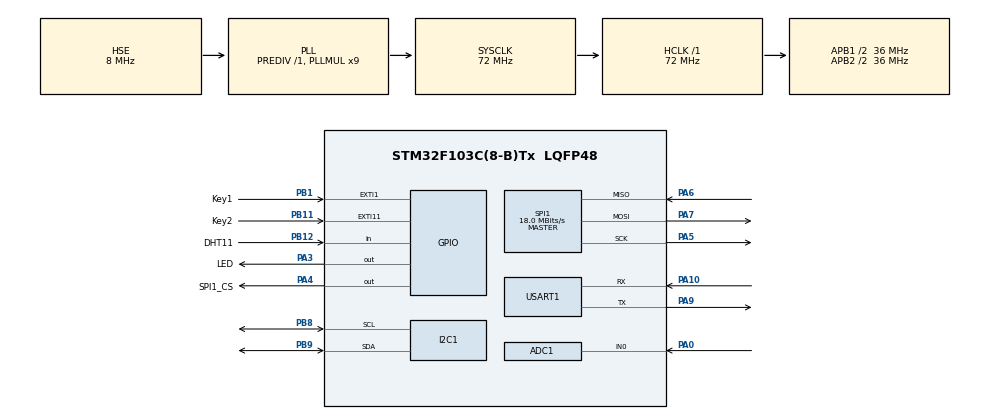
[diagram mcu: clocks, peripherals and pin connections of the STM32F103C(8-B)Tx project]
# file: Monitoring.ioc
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ADC1.Channel-0\#ChannelRegularConversion=ADC_CHANNEL_0
ADC1.ContinuousConvMode=DISABLE
ADC1.NbrOfConversionFlag=1
ADC1.Rank-0\#ChannelRegularConversion=1
ADC1.SamplingTime-0\#ChannelRegularConversion=ADC_SAMPLETIME_1CYCLE_5
ADC1.master=1
Dma.ADC1.2.Direction=DMA_PERIPH_TO_MEMORY
Dma.ADC1.2.Instance=DMA1_Channel1
Dma.ADC1.2.MemDataAlignment=DMA_MDATAALIGN_HALFWORD
Dma.ADC1.2.MemInc=DMA_MINC_ENABLE
Dma.ADC1.2.Mode=DMA_NORMAL
Dma.ADC1.2.PeriphDataAlignment=DMA_PDATAALIGN_HALFWORD
Dma.ADC1.2.PeriphInc=DMA_PINC_DISABLE
Dma.ADC1.2.Priority=DMA_PRIORITY_LOW
Dma.Request0=USART1_RX
Dma.Request1=USART1_TX
Dma.Request2=ADC1
Dma.USART1_RX.0.Direction=DMA_PERIPH_TO_MEMORY
Dma.USART1_RX.0.Instance=DMA1_Channel5
Dma.USART1_RX.0.MemDataAlignment=DMA_MDATAALIGN_BYTE
Dma.USART1_RX.0.MemInc=DMA_MINC_ENABLE
Dma.USART1_RX.0.Mode=DMA_NORMAL
Dma.USART1_RX.0.PeriphDataAlignment=DMA_PDATAALIGN_BYTE
Dma.USART1_RX.0.PeriphInc=DMA_PINC_DISABLE
Dma.USART1_RX.0.Priority=DMA_PRIORITY_LOW
Dma.USART1_TX.1.Direction=DMA_MEMORY_TO_PERIPH
Dma.USART1_TX.1.Instance=DMA1_Channel4
Dma.USART1_TX.1.MemDataAlignment=DMA_MDATAALIGN_BYTE
Dma.USART1_TX.1.MemInc=DMA_MINC_ENABLE
Dma.USART1_TX.1.Mode=DMA_NORMAL
Dma.USART1_TX.1.PeriphDataAlignment=DMA_PDATAALIGN_BYTE
Dma.USART1_TX.1.PeriphInc=DMA_PINC_DISABLE
Dma.USART1_TX.1.Priority=DMA_PRIORITY_LOW
FREERTOS.BinarySemaphores01=ADCBinarySem,Dynamic,NULL,Depleted
FREERTOS.Events01=AlarmEvent,Dynamic,NULL
FREERTOS.Mutexes01=myMutex01,Dynamic,NULL,Available
FREERTOS.Queues01=LogQueue,4,LogData_t,0,Dynamic,NULL,NULL
FREERTOS.Tasks01=CollectTask,24,128,StartCollectTask,Default,NULL,Dynamic,NULL,NULL;ShowTask,8,256,StartShowTask,Default,NULL,Dynamic,NULL,NULL;SerialTask,8,256,StartSerialTask,Default,NULL,Dynamic,NULL,NULL;AlarmTask,25,128,StartAlarmTask,Default,NULL,Dynamic,NULL,NULL;KeyTask,8,128,StartKeyTask,Default,NULL,Dynamic,NULL,NULL
FREERTOS.Timers01=CollectTimer,Callback01,osTimerPeriodic,Default,NULL,Dynamic,NULL
FREERTOS.configTOTAL_HEAP_SIZE=8192
Mcu.Family=STM32F1
Mcu.Name=STM32F103C(8-B)Tx
Mcu.Package=LQFP48
NVIC.ADC1_2_IRQn=true\:5\:0\:false\:false\:true\:true\:true\:true\:true
NVIC.DMA1_Channel1_IRQn=true\:5\:0\:false\:false\:true\:true\:false\:true\:true
NVIC.DMA1_Channel4_IRQn=true\:5\:0\:false\:false\:true\:true\:false\:true\:true
NVIC.DMA1_Channel5_IRQn=true\:5\:0\:false\:false\:true\:true\:false\:true\:true
NVIC.EXTI15_10_IRQn=true\:5\:0\:false\:false\:true\:true\:true\:true\:true
NVIC.EXTI1_IRQn=true\:5\:0\:false\:false\:true\:true\:true\:true\:true
NVIC.PriorityGroup=NVIC_PRIORITYGROUP_4
NVIC.TIM4_IRQn=true\:15\:0\:false\:false\:true\:false\:false\:true\:true
NVIC.TimeBase=TIM4_IRQn
NVIC.TimeBaseIP=TIM4
NVIC.USART1_IRQn=true\:5\:0\:false\:false\:true\:true\:true\:true\:true
PA0-WKUP.Signal=ADCx_IN0
PA10.Mode=Asynchronous
PA10.Signal=USART1_RX
PA13.Mode=Serial_Wire
PA13.Signal=SYS_JTMS-SWDIO
PA14.Mode=Serial_Wire
PA14.Signal=SYS_JTCK-SWCLK
PA3.GPIO_Label=LED
PA3.GPIO_Speed=GPIO_SPEED_FREQ_HIGH
PA3.Signal=GPIO_Output
PA4.GPIO_Label=SPI1_CS
PA4.GPIO_Speed=GPIO_SPEED_FREQ_HIGH
PA4.PinState=GPIO_PIN_SET
PA4.Signal=GPIO_Output
PA5.Mode=Full_Duplex_Master
PA5.Signal=SPI1_SCK
PA6.Mode=Full_Duplex_Master
PA6.Signal=SPI1_MISO
PA7.Mode=Full_Duplex_Master
PA7.Signal=SPI1_MOSI
PA9.Mode=Asynchronous
PA9.Signal=USART1_TX
PB1.GPIO_Label=Key1
PB1.GPIO_ModeDefaultEXTI=GPIO_MODE_IT_FALLING
PB1.GPIO_PuPd=GPIO_PULLUP
PB1.Signal=GPXTI1
PB11.GPIO_Label=Key2
PB11.GPIO_ModeDefaultEXTI=GPIO_MODE_IT_FALLING
PB11.GPIO_PuPd=GPIO_PULLUP
PB11.Signal=GPXTI11
PB12.GPIO_Label=DHT11
PB12.GPIO_PuPd=GPIO_PULLUP
PB12.Signal=GPIO_Input
PB8.Mode=I2C
PB8.Signal=I2C1_SCL
PB9.Mode=I2C
PB9.Signal=I2C1_SDA
PD0-OSC_IN.Mode=HSE-External-Oscillator
PD0-OSC_IN.Signal=RCC_OSC_IN
PD1-OSC_OUT.Mode=HSE-External-Oscillator
PD1-OSC_OUT.Signal=RCC_OSC_OUT
ProjectManager.HeapSize=0x200
ProjectManager.StackSize=0x400
ProjectManager.TargetToolchain=MDK-ARM V5.32
RCC.ADCPresc=RCC_ADCPCLK2_DIV4
RCC.AHBFreq_Value=72000000
RCC.APB1CLKDivider=RCC_HCLK_DIV2
RCC.APB1Freq_Value=36000000
RCC.APB1TimFreq_Value=72000000
RCC.APB2CLKDivider=RCC_HCLK_DIV2
RCC.APB2Freq_Value=36000000
RCC.APB2TimFreq_Value=72000000
RCC.HCLKFreq_Value=72000000
RCC.PLLMUL=RCC_PLL_MUL9
RCC.PLLSourceVirtual=RCC_PLLSOURCE_HSE
RCC.SYSCLKFreq_VALUE=72000000
RCC.SYSCLKSource=RCC_SYSCLKSOURCE_PLLCLK
RCC.USBFreq_Value=72000000
SH.ADCx_IN0.0=ADC1_IN0,IN0
SPI1.CalculateBaudRate=18.0 MBits/s
SPI1.Direction=SPI_DIRECTION_2LINES
SPI1.Mode=SPI_MODE_MASTER
SPI1.VirtualType=VM_MASTER
TIM2.AutoReloadPreload=TIM_AUTORELOAD_PRELOAD_ENABLE
TIM2.Prescaler=71
USART1.VirtualMode=VM_ASYNC
VP_FREERTOS_VS_CMSIS_V2.Mode=CMSIS_V2
VP_SYS_VS_tim4.Mode=TIM4
VP_TIM2_VS_ClockSourceINT.Mode=Internal
board=custom

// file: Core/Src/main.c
/* USER CODE BEGIN Header */
/**
  ******************************************************************************
  * @file           : main.c
  * @brief          : Main program body
  ******************************************************************************
  * @attention
  *
  * Copyright (c) 2026 STMicroelectronics.
  * All rights reserved.
  *
  * This software is licensed under terms that can be found in the LICENSE file
  * in the root directory of this software component.
  * If no LICENSE file comes with this software, it is provided AS-IS.
  *
  ******************************************************************************
  */
/* USER CODE END Header */
#include "main.h"
#include "cmsis_os.h"
#include "adc.h"
#include "dma.h"
#include "i2c.h"
#include "spi.h"
#include "tim.h"
#include "usart.h"
#include "gpio.h"

void SystemClock_Config(void);
void MX_FREERTOS_Init(void);

int main(void)
{

  /* MCU Configuration--------------------------------------------------------*/

  /* Reset of all peripherals, Initializes the Flash interface and the Systick. */
  HAL_Init();

  /* Configure the system clock */
  SystemClock_Config();

  /* Initialize all configured peripherals */
  MX_GPIO_Init();
  MX_DMA_Init();
  MX_I2C1_Init();
  MX_USART1_UART_Init();
  MX_TIM2_Init();
  MX_ADC1_Init();
  MX_SPI1_Init();

  /* Init scheduler */
  osKernelInitialize();  /* Call init function for freertos objects (in cmsis_os2.c) */
  MX_FREERTOS_Init();

  /* Start scheduler */
  osKernelStart();

  /* We should never get here as control is now taken by the scheduler */

  /* Infinite loop */
  while (1)
  {

  }
}

void SystemClock_Config(void)
{
  RCC_OscInitTypeDef RCC_OscInitStruct = {0};
  RCC_ClkInitTypeDef RCC_ClkInitStruct = {0};
  RCC_PeriphCLKInitTypeDef PeriphClkInit = {0};

  /** Initializes the RCC Oscillators according to the specified parameters
  * in the RCC_OscInitTypeDef structure.
  */
  RCC_OscInitStruct.OscillatorType = RCC_OSCILLATORTYPE_HSE;
  RCC_OscInitStruct.HSEState = RCC_HSE_ON;
  RCC_OscInitStruct.HSEPredivValue = RCC_HSE_PREDIV_DIV1;
  RCC_OscInitStruct.HSIState = RCC_HSI_ON;
  RCC_OscInitStruct.PLL.PLLState = RCC_PLL_ON;
  RCC_OscInitStruct.PLL.PLLSource = RCC_PLLSOURCE_HSE;
  RCC_OscInitStruct.PLL.PLLMUL = RCC_PLL_MUL9;
  if (HAL_RCC_OscConfig(&RCC_OscInitStruct) != HAL_OK)
  {
    Error_Handler();
  }

  /** Initializes the CPU, AHB and APB buses clocks
  */
  RCC_ClkInitStruct.ClockType = RCC_CLOCKTYPE_HCLK|RCC_CLOCKTYPE_SYSCLK
                              |RCC_CLOCKTYPE_PCLK1|RCC_CLOCKTYPE_PCLK2;
  RCC_ClkInitStruct.SYSCLKSource = RCC_SYSCLKSOURCE_PLLCLK;
  RCC_ClkInitStruct.AHBCLKDivider = RCC_SYSCLK_DIV1;
  RCC_ClkInitStruct.APB1CLKDivider = RCC_HCLK_DIV2;
  RCC_ClkInitStruct.APB2CLKDivider = RCC_HCLK_DIV2;

  if (HAL_RCC_ClockConfig(&RCC_ClkInitStruct, FLASH_LATENCY_2) != HAL_OK)
  {
    Error_Handler();
  }
  PeriphClkInit.PeriphClockSelection = RCC_PERIPHCLK_ADC;
  PeriphClkInit.AdcClockSelection = RCC_ADCPCLK2_DIV4;
  if (HAL_RCCEx_PeriphCLKConfig(&PeriphClkInit) != HAL_OK)
  {
    Error_Handler();
  }
}

void HAL_TIM_PeriodElapsedCallback(TIM_HandleTypeDef *htim)
{
  if (htim->Instance == TIM4)
  {
    HAL_IncTick();
  }
}

void Error_Handler(void)
{
  __disable_irq();
  while (1)
  {
  }
}

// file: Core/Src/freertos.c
/* USER CODE BEGIN Header */
/**
  ******************************************************************************
  * File Name          : freertos.c
  * Description        : Code for freertos applications
  ******************************************************************************
  * @attention
  *
  * Copyright (c) 2026 STMicroelectronics.
  * All rights reserved.
  *
  * This software is licensed under terms that can be found in the LICENSE file
  * in the root directory of this software component.
  * If no LICENSE file comes with this software, it is provided AS-IS.
  *
  ******************************************************************************
  */
/* USER CODE END Header */

#include "FreeRTOS.h"
#include "task.h"
#include "main.h"
#include "cmsis_os.h"

/* USER CODE BEGIN Includes */
#include "app_config.h"
#include "app_rtos.h"
#include  "app_task.h"
#include "bsp_oled.h"
/* USER CODE END Includes */

/* Definitions for CollectTask */
osThreadId_t CollectTaskHandle;
const osThreadAttr_t CollectTask_attributes = {
  .name = "CollectTask",
  .stack_size = 128 * 4,
  .priority = (osPriority_t) osPriorityNormal,
};
/* Definitions for ShowTask */
osThreadId_t ShowTaskHandle;
const osThreadAttr_t ShowTask_attributes = {
  .name = "ShowTask",
  .stack_size = 256 * 4,
  .priority = (osPriority_t) osPriorityLow,
};
/* Definitions for SerialTask */
osThreadId_t SerialTaskHandle;
const osThreadAttr_t SerialTask_attributes = {
  .name = "SerialTask",
  .stack_size = 256 * 4,
  .priority = (osPriority_t) osPriorityLow,
};
/* Definitions for AlarmTask */
osThreadId_t AlarmTaskHandle;
const osThreadAttr_t AlarmTask_attributes = {
  .name = "AlarmTask",
  .stack_size = 128 * 4,
  .priority = (osPriority_t) osPriorityNormal1,
};
/* Definitions for KeyTask */
osThreadId_t KeyTaskHandle;
const osThreadAttr_t KeyTask_attributes = {
  .name = "KeyTask",
  .stack_size = 128 * 4,
  .priority = (osPriority_t) osPriorityLow,
};
/* Definitions for LogQueue */
osMessageQueueId_t LogQueueHandle;
const osMessageQueueAttr_t LogQueue_attributes = {
  .name = "LogQueue"
};
/* Definitions for CollectTimer */
osTimerId_t CollectTimerHandle;
const osTimerAttr_t CollectTimer_attributes = {
  .name = "CollectTimer"
};
/* Definitions for myMutex01 */
osMutexId_t myMutex01Handle;
const osMutexAttr_t myMutex01_attributes = {
  .name = "myMutex01"
};
/* Definitions for ADCBinarySem */
osSemaphoreId_t ADCBinarySemHandle;
const osSemaphoreAttr_t ADCBinarySem_attributes = {
  .name = "ADCBinarySem"
};
/* Definitions for AlarmEvent */
osEventFlagsId_t AlarmEventHandle;
const osEventFlagsAttr_t AlarmEvent_attributes = {
  .name = "AlarmEvent"
};

void StartCollectTask(void *argument);
void StartShowTask(void *argument);
void StartSerialTask(void *argument);
void StartAlarmTask(void *argument);
void StartKeyTask(void *argument);
void Callback01(void *argument);

void MX_FREERTOS_Init(void); /* (MISRA C 2004 rule 8.1) */

void MX_FREERTOS_Init(void) {
  /* USER CODE BEGIN Init */
	OLED_Init();
  /* USER CODE END Init */
  /* Create the mutex(es) */
  /* creation of myMutex01 */
  myMutex01Handle = osMutexNew(&myMutex01_attributes);

  /* Create the semaphores(s) */
  /* creation of ADCBinarySem */
  ADCBinarySemHandle = osSemaphoreNew(1, 0, &ADCBinarySem_attributes);

  /* Create the timer(s) */
  /* creation of CollectTimer */
  CollectTimerHandle = osTimerNew(Callback01, osTimerPeriodic, NULL, &CollectTimer_attributes);

  /* Create the queue(s) */
  /* creation of LogQueue */
  LogQueueHandle = osMessageQueueNew (4, sizeof(LogData_t), &LogQueue_attributes);

  /* Create the thread(s) */
  /* creation of CollectTask */
  CollectTaskHandle = osThreadNew(StartCollectTask, NULL, &CollectTask_attributes);

  /* creation of ShowTask */
  ShowTaskHandle = osThreadNew(StartShowTask, NULL, &ShowTask_attributes);

  /* creation of SerialTask */
  SerialTaskHandle = osThreadNew(StartSerialTask, NULL, &SerialTask_attributes);

  /* creation of AlarmTask */
  AlarmTaskHandle = osThreadNew(StartAlarmTask, NULL, &AlarmTask_attributes);

  /* creation of KeyTask */
  KeyTaskHandle = osThreadNew(StartKeyTask, NULL, &KeyTask_attributes);

  /* creation of AlarmEvent */
  AlarmEventHandle = osEventFlagsNew(&AlarmEvent_attributes);

}

void StartCollectTask(void *argument)
{
  /* USER CODE BEGIN StartCollectTask */
  /* Infinite loop */
	CollectTask_Entry(argument);
	/* USER CODE END StartCollectTask */
}

void StartShowTask(void *argument)
{
  /* USER CODE BEGIN StartShowTask */
  /* Infinite loop */
	DisplayTask_Entry(argument);
  /* USER CODE END StartShowTask */
}

void StartSerialTask(void *argument)
{
  /* USER CODE BEGIN StartSerialTask */
  /* Infinite loop */

	SerialTask_Entry(argument);

  /* USER CODE END StartSerialTask */
}

void StartAlarmTask(void *argument)
{
  /* USER CODE BEGIN StartAlarmTask */
  /* Infinite loop */
	AlarmTask_Entry(argument);
  /* USER CODE END StartAlarmTask */
}

void StartKeyTask(void *argument)
{
  /* USER CODE BEGIN StartKeyTask */

	KeyTask_Entry(argument);

	/* Infinite loop */
  /* USER CODE END StartKeyTask */
}

/* Callback01 function */
void Callback01(void *argument)
{
  /* USER CODE BEGIN Callback01 */
	xTaskNotifyGive(CollectTaskHandle);   /* 到达采集周期，唤醒采集任务 */
  /* USER CODE END Callback01 */
}
